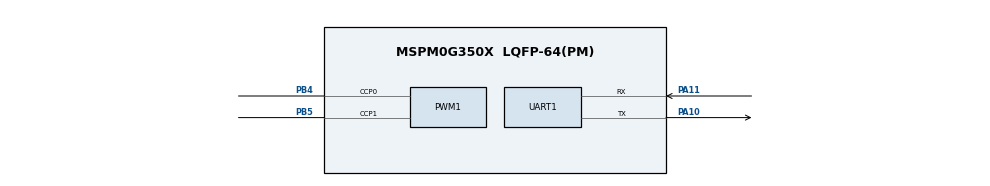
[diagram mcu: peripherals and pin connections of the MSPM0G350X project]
/**
 * @cliArgs --device "MSPM0G350X" --part "Default" --package "LQFP-64(PM)" --product "mspm0_sdk@2.04.00.06"
 * @versions {"tool":"1.22.0+3893"}
 */

/**
 * Import the modules used in this configuration.
 */
const ADC12   = scripting.addModule("/ti/driverlib/ADC12", {}, false);
const ADC121  = ADC12.addInstance();
const GPIO    = scripting.addModule("/ti/driverlib/GPIO", {}, false);
const GPIO1   = GPIO.addInstance();
const GPIO2   = GPIO.addInstance();
const GPIO3   = GPIO.addInstance();
const GPIO4   = GPIO.addInstance();
const GPIO5   = GPIO.addInstance();
const GPIO6   = GPIO.addInstance();
const GPIO7   = GPIO.addInstance();
const GPIO8   = GPIO.addInstance();
const GPIO9   = GPIO.addInstance();
const I2C     = scripting.addModule("/ti/driverlib/I2C", {}, false);
const I2C1    = I2C.addInstance();
const PWM     = scripting.addModule("/ti/driverlib/PWM", {}, false);
const PWM1    = PWM.addInstance();
const SYSCTL  = scripting.addModule("/ti/driverlib/SYSCTL");
const SYSTICK = scripting.addModule("/ti/driverlib/SYSTICK");
const TIMER   = scripting.addModule("/ti/driverlib/TIMER", {}, false);
const TIMER1  = TIMER.addInstance();
const TIMER2  = TIMER.addInstance();
const UART    = scripting.addModule("/ti/driverlib/UART", {}, false);
const UART1   = UART.addInstance();

/**
 * Write custom configuration values to the imported modules.
 */
ADC121.$name               = "ADC12_0";
ADC121.powerDownMode       = "DL_ADC12_POWER_DOWN_MODE_MANUAL";
ADC121.sampleTime0         = "125us";
ADC121.enabledInterrupts   = ["DL_ADC12_INTERRUPT_MEM0_RESULT_LOADED"];
ADC121.sampClkDiv          = "DL_ADC12_CLOCK_DIVIDE_8";
ADC121.adcPin0Config.$name = "ti_driverlib_gpio_GPIOPinGeneric6";

const Board = scripting.addModule("/ti/driverlib/Board", {}, false);

GPIO1.$name                          = "GPIO_LED";
GPIO1.associatedPins[0].$name        = "PIN_LED_1";
GPIO1.associatedPins[0].assignedPort = "PORTB";
GPIO1.associatedPins[0].assignedPin  = "22";

GPIO2.$name                              = "GPIO_KEY";
GPIO2.associatedPins.create(5);
GPIO2.associatedPins[0].$name            = "PIN_KEY_S1";
GPIO2.associatedPins[0].direction        = "INPUT";
GPIO2.associatedPins[0].assignedPort     = "PORTB";
GPIO2.associatedPins[0].internalResistor = "PULL_UP";
GPIO2.associatedPins[0].assignedPin      = "23";
GPIO2.associatedPins[1].direction        = "INPUT";
GPIO2.associatedPins[1].assignedPort     = "PORTB";
GPIO2.associatedPins[1].assignedPin      = "17";
GPIO2.associatedPins[1].internalResistor = "PULL_UP";
GPIO2.associatedPins[1].$name            = "PIN_KEY_SW2";
GPIO2.associatedPins[2].direction        = "INPUT";
GPIO2.associatedPins[2].assignedPort     = "PORTB";
GPIO2.associatedPins[2].assignedPin      = "18";
GPIO2.associatedPins[2].internalResistor = "PULL_UP";
GPIO2.associatedPins[2].$name            = "PIN_KEY_SW3";
GPIO2.associatedPins[3].direction        = "INPUT";
GPIO2.associatedPins[3].internalResistor = "PULL_UP";
GPIO2.associatedPins[3].assignedPort     = "PORTB";
GPIO2.associatedPins[3].assignedPin      = "19";
GPIO2.associatedPins[3].$name            = "PIN_KEY_SW4";
GPIO2.associatedPins[4].direction        = "INPUT";
GPIO2.associatedPins[4].internalResistor = "PULL_UP";
GPIO2.associatedPins[4].assignedPort     = "PORTB";
GPIO2.associatedPins[4].assignedPin      = "20";
GPIO2.associatedPins[4].$name            = "PIN_KEY_SW5";

GPIO3.$name                          = "GPIO_BUZZ";
GPIO3.associatedPins[0].$name        = "PIN_BUZZ_1";
GPIO3.associatedPins[0].assignedPort = "PORTB";
GPIO3.associatedPins[0].assignedPin  = "1";
GPIO3.associatedPins[0].initialValue = "SET";

GPIO4.$name                          = "GPIO_Motor";
GPIO4.associatedPins.create(4);
GPIO4.associatedPins[0].$name        = "PIN_Motor_AIN1";
GPIO4.associatedPins[0].assignedPort = "PORTB";
GPIO4.associatedPins[0].assignedPin  = "13";
GPIO4.associatedPins[1].$name        = "PIN_Motor_AIN2";
GPIO4.associatedPins[1].assignedPort = "PORTB";
GPIO4.associatedPins[1].assignedPin  = "12";
GPIO4.associatedPins[2].$name        = "PIN_Motor_BIN1";
GPIO4.associatedPins[2].assignedPort = "PORTB";
GPIO4.associatedPins[2].assignedPin  = "26";
GPIO4.associatedPins[3].$name        = "PIN_Motor_BIN2";
GPIO4.associatedPins[3].assignedPort = "PORTB";
GPIO4.associatedPins[3].assignedPin  = "27";

GPIO5.$name                          = "GPIO_OLED";
GPIO5.associatedPins.create(2);
GPIO5.associatedPins[0].$name        = "PIN_SCL";
GPIO5.associatedPins[0].assignedPort = "PORTA";
GPIO5.associatedPins[0].assignedPin  = "31";
GPIO5.associatedPins[1].$name        = "PIN_SDA";
GPIO5.associatedPins[1].assignedPort = "PORTA";
GPIO5.associatedPins[1].assignedPin  = "28";

GPIO6.$name                          = "GPIO_Encoder";
GPIO6.associatedPins.create(4);
GPIO6.associatedPins[0].$name        = "PIN_LA";
GPIO6.associatedPins[0].direction    = "INPUT";
GPIO6.associatedPins[0].assignedPort = "PORTB";
GPIO6.associatedPins[0].assignedPin  = "14";
GPIO6.associatedPins[0].interruptEn  = true;
GPIO6.associatedPins[0].polarity     = "RISE_FALL";
GPIO6.associatedPins[1].$name        = "PIN_LB";
GPIO6.associatedPins[1].direction    = "INPUT";
GPIO6.associatedPins[1].assignedPort = "PORTA";
GPIO6.associatedPins[1].assignedPin  = "15";
GPIO6.associatedPins[1].interruptEn  = true;
GPIO6.associatedPins[1].polarity     = "RISE_FALL";
GPIO6.associatedPins[2].$name        = "PIN_RA";
GPIO6.associatedPins[2].direction    = "INPUT";
GPIO6.associatedPins[2].assignedPort = "PORTA";
GPIO6.associatedPins[2].assignedPin  = "1";
GPIO6.associatedPins[2].interruptEn  = true;
GPIO6.associatedPins[2].polarity     = "RISE_FALL";
GPIO6.associatedPins[3].$name        = "PIN_RB";
GPIO6.associatedPins[3].assignedPort = "PORTA";
GPIO6.associatedPins[3].assignedPin  = "7";
GPIO6.associatedPins[3].direction    = "INPUT";
GPIO6.associatedPins[3].interruptEn  = true;
GPIO6.associatedPins[3].polarity     = "RISE_FALL";

GPIO7.$name                          = "GPIO_HSR04";
GPIO7.associatedPins.create(2);
GPIO7.associatedPins[0].$name        = "PIN_Trig";
GPIO7.associatedPins[0].assignedPort = "PORTA";
GPIO7.associatedPins[0].assignedPin  = "8";
GPIO7.associatedPins[1].$name        = "PIN_Echo";
GPIO7.associatedPins[1].assignedPort = "PORTA";
GPIO7.associatedPins[1].assignedPin  = "9";
GPIO7.associatedPins[1].direction    = "INPUT";
GPIO7.associatedPins[1].interruptEn  = true;
GPIO7.associatedPins[1].polarity     = "RISE_FALL";

GPIO8.$name                          = "GPIO_MPU6050";
GPIO8.associatedPins[0].$name        = "PIN_INT";
GPIO8.associatedPins[0].direction    = "INPUT";
GPIO8.associatedPins[0].interruptEn  = true;
GPIO8.associatedPins[0].assignedPort = "PORTB";
GPIO8.associatedPins[0].assignedPin  = "0";
GPIO8.associatedPins[0].polarity     = "RISE";

GPIO9.$name                          = "GPIO_Step_Motor";
GPIO9.associatedPins.create(3);
GPIO9.associatedPins[0].assignedPort = "PORTB";
GPIO9.associatedPins[0].$name        = "PIN_ENA";
GPIO9.associatedPins[0].assignedPin  = "25";
GPIO9.associatedPins[1].assignedPort = "PORTB";
GPIO9.associatedPins[1].$name        = "PIN_STEP";
GPIO9.associatedPins[1].assignedPin  = "21";
GPIO9.associatedPins[2].assignedPort = "PORTB";
GPIO9.associatedPins[2].$name        = "PIN_DIR";
GPIO9.associatedPins[2].assignedPin  = "24";

I2C1.$name                             = "I2C_MPU6050";
I2C1.basicEnableController             = true;
I2C1.basicControllerStandardBusSpeed   = "Fast";
I2C1.sdaPinConfig.hideOutputInversion  = scripting.forceWrite(false);
I2C1.sdaPinConfig.onlyInternalResistor = scripting.forceWrite(false);
I2C1.sdaPinConfig.passedPeripheralType = scripting.forceWrite("Digital");
I2C1.sdaPinConfig.$name                = "ti_driverlib_gpio_GPIOPinGeneric4";
I2C1.sclPinConfig.hideOutputInversion  = scripting.forceWrite(false);
I2C1.sclPinConfig.onlyInternalResistor = scripting.forceWrite(false);
I2C1.sclPinConfig.passedPeripheralType = scripting.forceWrite("Digital");
I2C1.sclPinConfig.$name                = "ti_driverlib_gpio_GPIOPinGeneric5";

PWM1.clockDivider                       = 8;
PWM1.timerStartTimer                    = true;
PWM1.$name                              = "TimerA1_PWM";
PWM1.peripheral.$assign                 = "TIMA1";
PWM1.peripheral.ccp0Pin.$assign         = "PB4";
PWM1.peripheral.ccp1Pin.$assign         = "PB5";
PWM1.PWM_CHANNEL_0.$name                = "ti_driverlib_pwm_PWMTimerCC0";
PWM1.PWM_CHANNEL_1.$name                = "ti_driverlib_pwm_PWMTimerCC1";
PWM1.ccp0PinConfig.direction            = scripting.forceWrite("OUTPUT");
PWM1.ccp0PinConfig.hideOutputInversion  = scripting.forceWrite(false);
PWM1.ccp0PinConfig.onlyInternalResistor = scripting.forceWrite(false);
PWM1.ccp0PinConfig.passedPeripheralType = scripting.forceWrite("Digital");
PWM1.ccp0PinConfig.$name                = "ti_driverlib_gpio_GPIOPinGeneric0";
PWM1.ccp1PinConfig.direction            = scripting.forceWrite("OUTPUT");
PWM1.ccp1PinConfig.hideOutputInversion  = scripting.forceWrite(false);
PWM1.ccp1PinConfig.onlyInternalResistor = scripting.forceWrite(false);
PWM1.ccp1PinConfig.passedPeripheralType = scripting.forceWrite("Digital");
PWM1.ccp1PinConfig.$name                = "ti_driverlib_gpio_GPIOPinGeneric1";

SYSCTL.forceDefaultClkConfig = true;
SYSCTL.clockTreeEn           = true;

SYSTICK.periodEnable    = true;
SYSTICK.period          = 32000;
SYSTICK.interruptEnable = true;
SYSTICK.systickEnable   = true;

TIMER1.$name              = "TIMER_0";
TIMER1.timerClkPrescale   = 256;
TIMER1.timerMode          = "PERIODIC";
TIMER1.interrupts         = ["ZERO"];
TIMER1.timerPeriod        = "100ms";
TIMER1.peripheral.$assign = "TIMG0";

TIMER2.$name            = "TIMER_HSR04";
TIMER2.timerClkPrescale = 32;
TIMER2.timerMode        = "ONE_SHOT_UP";
TIMER2.timerPeriod      = "25ms";
TIMER2.interrupts       = ["LOAD"];

UART1.$name                    = "UART_0";
UART1.targetBaudRate           = 115200;
UART1.enabledInterrupts        = ["RX"];
UART1.peripheral.rxPin.$assign = "PA11";
UART1.peripheral.txPin.$assign = "PA10";
UART1.txPinConfig.$name        = "ti_driverlib_gpio_GPIOPinGeneric2";
UART1.rxPinConfig.$name        = "ti_driverlib_gpio_GPIOPinGeneric3";

/**
 * Pinmux solution for unlocked pins/peripherals. This ensures that minor changes to the automatic solver in a future
 * version of the tool will not impact the pinmux you originally saw.  These lines can be completely deleted in order to
 * re-solve from scratch.
 */
ADC121.peripheral.$suggestSolution           = "ADC0";
ADC121.peripheral.adcPin0.$suggestSolution   = "PA27";
Board.peripheral.$suggestSolution            = "DEBUGSS";
Board.peripheral.swclkPin.$suggestSolution   = "PA20";
Board.peripheral.swdioPin.$suggestSolution   = "PA19";
GPIO1.associatedPins[0].pin.$suggestSolution = "PB22";
GPIO2.associatedPins[0].pin.$suggestSolution = "PB23";
GPIO2.associatedPins[1].pin.$suggestSolution = "PB17";
GPIO2.associatedPins[2].pin.$suggestSolution = "PB18";
GPIO2.associatedPins[3].pin.$suggestSolution = "PB19";
GPIO2.associatedPins[4].pin.$suggestSolution = "PB20";
GPIO3.associatedPins[0].pin.$suggestSolution = "PB1";
GPIO4.associatedPins[0].pin.$suggestSolution = "PB13";
GPIO4.associatedPins[1].pin.$suggestSolution = "PB12";
GPIO4.associatedPins[2].pin.$suggestSolution = "PB26";
GPIO4.associatedPins[3].pin.$suggestSolution = "PB27";
GPIO5.associatedPins[0].pin.$suggestSolution = "PA31";
GPIO5.associatedPins[1].pin.$suggestSolution = "PA28";
GPIO6.associatedPins[0].pin.$suggestSolution = "PB14";
GPIO6.associatedPins[1].pin.$suggestSolution = "PA15";
GPIO6.associatedPins[2].pin.$suggestSolution = "PA1";
GPIO6.associatedPins[3].pin.$suggestSolution = "PA7";
GPIO7.associatedPins[0].pin.$suggestSolution = "PA8";
GPIO7.associatedPins[1].pin.$suggestSolution = "PA9";
GPIO8.associatedPins[0].pin.$suggestSolution = "PB0";
GPIO9.associatedPins[0].pin.$suggestSolution = "PB25";
GPIO9.associatedPins[1].pin.$suggestSolution = "PB21";
GPIO9.associatedPins[2].pin.$suggestSolution = "PB24";
I2C1.peripheral.$suggestSolution             = "I2C1";
I2C1.peripheral.sdaPin.$suggestSolution      = "PA16";
I2C1.peripheral.sclPin.$suggestSolution      = "PA17";
TIMER2.peripheral.$suggestSolution           = "TIMA0";
UART1.peripheral.$suggestSolution            = "UART0";
